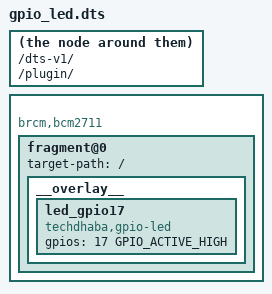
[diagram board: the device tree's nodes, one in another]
/dts-v1/;
/plugin/;
#include <dt-bindings/gpio/gpio.h>

{
    compatible = "brcm,bcm2711";

    fragment@0 {
        target-path = "/";
        __overlay__ {
            led_gpio17 {
                compatible = "techdhaba,gpio-led";
                gpios = <17 GPIO_ACTIVE_HIGH>;
                status = "okay";
            };
        };
    };
};

